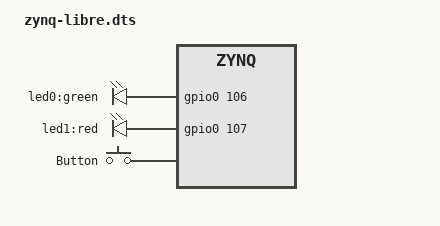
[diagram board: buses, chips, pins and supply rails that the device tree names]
// SPDX-License-Identifier: GPL-2.0
/*
 *
 * hdl_project: <libre>
 * board_revision: <5>
 *
 */
/dts-v1/;
#include "zynq-libre.dtsi"


// &axi_i2c0 {
// 	current_limiter@5a {
// 		compatible = "adi,adm1177";
// 		reg = <0x5a>;
// 		adi,r-sense-mohm = <50>; /* 50 mOhm */
// 		adi,shutdown-threshold-ma = <1059>; /* 1.059 A */
// 		adi,vrange-high-enable;
// 	};
// };


&adc0_ad9364 {
	/* This property is controlled by u-boot environment. */
	adi,2rx-2tx-mode-enable;
};

&cf_ad9364_dac_core_0 {
	/* This property is controlled by u-boot environment. */
	compatible = "adi,axi-ad9361-dds-6.00.a";
};


/ {
	
	leds {
		compatible = "gpio-leds";
		led0 {
			label = "led0:green";
			gpios = <&gpio0 106 0>;
			linux,default-trigger = "heartbeat";
		};
		led1 {
			label = "led1:red";
			gpios = <&gpio0 107 0>;
			default-state = "off";
		};
	};

	gpio_keys {
		compatible = "gpio-keys";
		#address-cells = <1>;
		#size-cells = <0>;

		button {
			interrupt-parent = <&gpio0>;
			interrupts = <12 IRQ_TYPE_EDGE_FALLING>;
			label = "Button";
			linux,code = <BTN_MISC>;
		};

	};
};


	
